AUTOSAR XML (schema 4-0-3)
standard types defined: Boolean, UInt32
package /AUTOSAR_Platform/DataConstrs
  range DC_Boolean: raw 0..1
package /PATAC/MSM/ComponentTypes
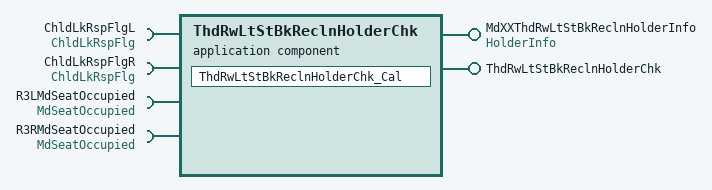
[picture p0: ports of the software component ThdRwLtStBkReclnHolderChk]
  application sw component type ThdRwLtStBkReclnHolderChk
    provide port MdXXThdRwLtStBkReclnHolderInfo: nonqueued-sender-com-spec{data-element=HolderInfo/Val, init-value=0}, provided-interface=HolderInfo
    provide port ThdRwLtStBkReclnHolderChk: server-com-spec{operation=Cal, queue-length=1}, provided-interface=ThdRwLtStBkReclnHolderChk
    4 x require port:
      ChldLkRspFlgL: nonqueued-receiver-com-spec{data-element=ChldLkRspFlg/Val, filter=data-filter-type=ALWAYS, init-value=0}, required-interface=ChldLkRspFlg
      ChldLkRspFlgR: nonqueued-receiver-com-spec{data-element=ChldLkRspFlg/Val, filter=data-filter-type=ALWAYS, init-value=0}, required-interface=ChldLkRspFlg
      R3LMdSeatOccupied: nonqueued-receiver-com-spec{data-element=MdSeatOccupied/Val, filter=data-filter-type=ALWAYS, init-value=0}, required-interface=MdSeatOccupied
      R3RMdSeatOccupied: nonqueued-receiver-com-spec{data-element=MdSeatOccupied/Val, filter=data-filter-type=ALWAYS, init-value=0}, required-interface=MdSeatOccupied
    behavior ThdRwLtStBkReclnHolderChk_InternalBehavior
      operation invoked event OIT_ThdRwLtStBkReclnHolderChk_Cal_ThdRwLtStBkReclnHolderChk_Cal: start-on-event=ThdRwLtStBkReclnHolderChk_Cal, operation=ThdRwLtStBkReclnHolderChk.Cal
      runnable ThdRwLtStBkReclnHolderChk_Cal
        data-receive-point-by-arguments:
          4 x access:
            REC_ChldLkRspFlgL_Val: accessed-variable=ChldLkRspFlgL.Val
            REC_ChldLkRspFlgR_Val: accessed-variable=ChldLkRspFlgR.Val
            REC_R3LMdSeatOccupied_Val: accessed-variable=R3LMdSeatOccupied.Val
            REC_R3RMdSeatOccupied_Val: accessed-variable=R3RMdSeatOccupied.Val
        data-send-points:
          access SEND_MdXXThdRwLtStBkReclnHolderInfo_Val: accessed-variable=MdXXThdRwLtStBkReclnHolderInfo.Val
  swc implementation ThdRwLtStBkReclnHolderChk_Implementation: behavior=ThdRwLtStBkReclnHolderChk_InternalBehavior
    code-descriptors:
      code Default: artifact-descriptors=autosar-engineering-object={short-label=Default, category=SWSRC}
package /PATAC/MSM/ModeAdjust/PortInterface
  client server interface ThdRwLtStBkReclnHolderChk
    operation Cal
  sender receiver interface ChldLkRspFlg: invalidation-policy{data-element=ChldLkRspFlg/Val, handle-invalid=DONT-INVALIDATE}
    data Val: type=Boolean
  sender receiver interface HolderInfo: invalidation-policy{data-element=HolderInfo/Val, handle-invalid=DONT-INVALIDATE}
    data Val: type=UInt32
  sender receiver interface MdSeatOccupied: invalidation-policy{data-element=MdSeatOccupied/Val, handle-invalid=DONT-INVALIDATE}
    data Val: type=Boolean
